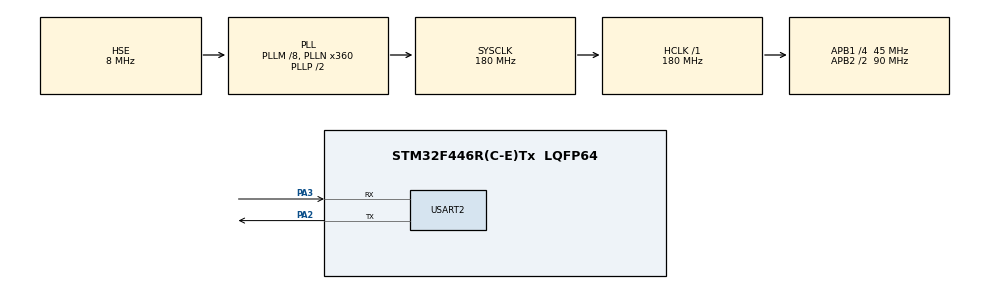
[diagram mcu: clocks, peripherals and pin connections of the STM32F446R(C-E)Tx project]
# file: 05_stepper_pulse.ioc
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Dma.Request0=USART2_RX
Dma.Request1=USART2_TX
Dma.USART2_RX.0.Direction=DMA_PERIPH_TO_MEMORY
Dma.USART2_RX.0.FIFOMode=DMA_FIFOMODE_DISABLE
Dma.USART2_RX.0.Instance=DMA1_Stream5
Dma.USART2_RX.0.MemDataAlignment=DMA_MDATAALIGN_BYTE
Dma.USART2_RX.0.MemInc=DMA_MINC_ENABLE
Dma.USART2_RX.0.Mode=DMA_CIRCULAR
Dma.USART2_RX.0.PeriphDataAlignment=DMA_PDATAALIGN_BYTE
Dma.USART2_RX.0.PeriphInc=DMA_PINC_DISABLE
Dma.USART2_RX.0.Priority=DMA_PRIORITY_LOW
Dma.USART2_TX.1.Direction=DMA_MEMORY_TO_PERIPH
Dma.USART2_TX.1.FIFOMode=DMA_FIFOMODE_DISABLE
Dma.USART2_TX.1.Instance=DMA1_Stream6
Dma.USART2_TX.1.MemDataAlignment=DMA_MDATAALIGN_BYTE
Dma.USART2_TX.1.MemInc=DMA_MINC_ENABLE
Dma.USART2_TX.1.Mode=DMA_NORMAL
Dma.USART2_TX.1.PeriphDataAlignment=DMA_PDATAALIGN_BYTE
Dma.USART2_TX.1.PeriphInc=DMA_PINC_DISABLE
Dma.USART2_TX.1.Priority=DMA_PRIORITY_LOW
Mcu.Family=STM32F4
Mcu.Name=STM32F446R(C-E)Tx
Mcu.Package=LQFP64
NVIC.DMA1_Stream5_IRQn=true\:0\:0\:false\:false\:true\:false\:true\:true
NVIC.DMA1_Stream6_IRQn=true\:0\:0\:false\:false\:true\:false\:true\:true
NVIC.PriorityGroup=NVIC_PRIORITYGROUP_0
NVIC.TIM2_IRQn=true\:0\:0\:false\:false\:true\:true\:true\:true
PA2.Mode=Asynchronous
PA2.Signal=USART2_TX
PA3.Mode=Asynchronous
PA3.Signal=USART2_RX
PH0-OSC_IN.Mode=HSE-External-Clock-Source
PH0-OSC_IN.Signal=RCC_OSC_IN
PH1-OSC_OUT.Mode=HSE-External-Clock-Source
PH1-OSC_OUT.Signal=RCC_OSC_OUT
ProjectManager.HeapSize=0x200
ProjectManager.StackSize=0x400
ProjectManager.TargetToolchain=CMake
RCC.AHBFreq_Value=180000000
RCC.APB1CLKDivider=RCC_HCLK_DIV4
RCC.APB1Freq_Value=45000000
RCC.APB1TimFreq_Value=90000000
RCC.APB2CLKDivider=RCC_HCLK_DIV2
RCC.APB2Freq_Value=90000000
RCC.APB2TimFreq_Value=180000000
RCC.CortexFreq_Value=180000000
RCC.FLatency-AdvancedSettings=FLASH_LATENCY_5
RCC.HCLKFreq_Value=180000000
RCC.HSE_VALUE=8000000
RCC.HSI_VALUE=16000000
RCC.LSE_VALUE=32768
RCC.PLLM=8
RCC.PLLN=360
RCC.PLLSourceVirtual=RCC_PLLSOURCE_HSE
RCC.SYSCLKFreq_VALUE=180000000
RCC.SYSCLKSource=RCC_SYSCLKSOURCE_PLLCLK
RCC.USBFreq_Value=180000000
RCC.VCOOutputFreq_Value=360000000
TIM2.Channel-Output\ Compare1\ No\ Output=TIM_CHANNEL_1
TIM2.Channel-Output\ Compare2\ No\ Output=TIM_CHANNEL_2
TIM2.Channel-Output\ Compare3\ No\ Output=TIM_CHANNEL_3
USART2.VirtualMode=VM_ASYNC
VP_TIM2_VS_ClockSourceINT.Mode=Internal
VP_TIM2_VS_no_output1.Mode=Output Compare1 No Output
VP_TIM2_VS_no_output2.Mode=Output Compare2 No Output
VP_TIM2_VS_no_output3.Mode=Output Compare3 No Output
board=NUCLEO-F446RE

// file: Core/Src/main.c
/* USER CODE BEGIN Header */
/**
  ******************************************************************************
  * @file           : main.c
  * @brief          : Main program body
  ******************************************************************************
  * @attention
  *
  * Copyright (c) 2026 STMicroelectronics.
  * All rights reserved.
  *
  * This software is licensed under terms that can be found in the LICENSE file
  * in the root directory of this software component.
  * If no LICENSE file comes with this software, it is provided AS-IS.
  *
  ******************************************************************************
  */
/* USER CODE END Header */
#include "main.h"

/* USER CODE BEGIN Includes */
#include "stdio.h"
#include "string.h"
/* USER CODE END Includes */

TIM_HandleTypeDef htim2;

UART_HandleTypeDef huart2;
DMA_HandleTypeDef hdma_usart2_rx;
DMA_HandleTypeDef hdma_usart2_tx;

/* USER CODE BEGIN PV */

#define TIM2_CLOCK    90000000UL  // 90 MHz

// Step counters — incremented each OC interrupt
volatile uint32_t stepsZ1 = 0;
volatile uint32_t stepsZ2 = 0;
volatile uint32_t stepsX  = 0;

// Current intervals (ticks between toggles)
uint32_t intervalZ1 = 0;
uint32_t intervalZ2 = 0;
uint32_t intervalX  = 0;

// UART buffer
char uartBuf[64];

/* USER CODE END PV */

void SystemClock_Config(void);
static void MX_GPIO_Init(void);
static void MX_DMA_Init(void);
static void MX_TIM2_Init(void);
static void MX_USART2_UART_Init(void);

/* USER CODE BEGIN 0 */
void setStepVelocity(TIM_HandleTypeDef *htim, uint32_t channel,
                     uint32_t *interval, float stepsPerSec)
{
    if (stepsPerSec < 1.0f)
    {
        // Stop — disable the channel interrupt
        __HAL_TIM_DISABLE_IT(htim, channel == TIM_CHANNEL_1 ? TIM_IT_CC1 :
                                    channel == TIM_CHANNEL_2 ? TIM_IT_CC2 :
                                                               TIM_IT_CC3);
        *interval = 0;
        return;
    }
    *interval = (uint32_t)(TIM2_CLOCK / stepsPerSec);
    // Schedule first compare event
    __HAL_TIM_SET_COMPARE(htim, channel,
        __HAL_TIM_GET_COUNTER(htim) + *interval);
    // Make sure interrupt is enabled
    __HAL_TIM_ENABLE_IT(htim, channel == TIM_CHANNEL_1 ? TIM_IT_CC1 :
                               channel == TIM_CHANNEL_2 ? TIM_IT_CC2 :
                                                          TIM_IT_CC3);
}
/* USER CODE END 0 */

int main(void)
{

  /* MCU Configuration--------------------------------------------------------*/

  /* Reset of all peripherals, Initializes the Flash interface and the Systick. */
  HAL_Init();

  /* Configure the system clock */
  SystemClock_Config();

  /* Initialize all configured peripherals */
  MX_GPIO_Init();
  MX_DMA_Init();
  MX_TIM2_Init();
  MX_USART2_UART_Init();
  /* USER CODE BEGIN 2 */
  HAL_TIM_OC_Start_IT(&htim2, TIM_CHANNEL_1);
  HAL_TIM_OC_Start_IT(&htim2, TIM_CHANNEL_2);
  HAL_TIM_OC_Start_IT(&htim2, TIM_CHANNEL_3);

  // Set all three axes to 500 steps/sec
  setStepVelocity(&htim2, TIM_CHANNEL_1, &intervalZ1, 500.0f);
  setStepVelocity(&htim2, TIM_CHANNEL_2, &intervalZ2, 500.0f);
  setStepVelocity(&htim2, TIM_CHANNEL_3, &intervalX,  500.0f);
  /* USER CODE END 2 */

  /* Infinite loop */
  while (1)
  {
    int len = snprintf(uartBuf, sizeof(uartBuf),
        "Z1:%lu  Z2:%lu  X:%lu\r\n", stepsZ1, stepsZ2, stepsX);
    HAL_UART_Transmit(&huart2, (uint8_t*)uartBuf, len, 100);
    HAL_Delay(500);
  }
}

void SystemClock_Config(void)
{
  RCC_OscInitTypeDef RCC_OscInitStruct = {0};
  RCC_ClkInitTypeDef RCC_ClkInitStruct = {0};

  /** Configure the main internal regulator output voltage
  */
  __HAL_RCC_PWR_CLK_ENABLE();
  __HAL_PWR_VOLTAGESCALING_CONFIG(PWR_REGULATOR_VOLTAGE_SCALE1);

  /** Initializes the RCC Oscillators according to the specified parameters
  * in the RCC_OscInitTypeDef structure.
  */
  RCC_OscInitStruct.OscillatorType = RCC_OSCILLATORTYPE_HSE;
  RCC_OscInitStruct.HSEState = RCC_HSE_BYPASS;
  RCC_OscInitStruct.PLL.PLLState = RCC_PLL_ON;
  RCC_OscInitStruct.PLL.PLLSource = RCC_PLLSOURCE_HSE;
  RCC_OscInitStruct.PLL.PLLM = 8;
  RCC_OscInitStruct.PLL.PLLN = 360;
  RCC_OscInitStruct.PLL.PLLP = RCC_PLLP_DIV2;
  RCC_OscInitStruct.PLL.PLLQ = 2;
  RCC_OscInitStruct.PLL.PLLR = 2;
  if (HAL_RCC_OscConfig(&RCC_OscInitStruct) != HAL_OK)
  {
    Error_Handler();
  }

  /** Activate the Over-Drive mode
  */
  if (HAL_PWREx_EnableOverDrive() != HAL_OK)
  {
    Error_Handler();
  }

  /** Initializes the CPU, AHB and APB buses clocks
  */
  RCC_ClkInitStruct.ClockType = RCC_CLOCKTYPE_HCLK|RCC_CLOCKTYPE_SYSCLK
                              |RCC_CLOCKTYPE_PCLK1|RCC_CLOCKTYPE_PCLK2;
  RCC_ClkInitStruct.SYSCLKSource = RCC_SYSCLKSOURCE_PLLCLK;
  RCC_ClkInitStruct.AHBCLKDivider = RCC_SYSCLK_DIV1;
  RCC_ClkInitStruct.APB1CLKDivider = RCC_HCLK_DIV4;
  RCC_ClkInitStruct.APB2CLKDivider = RCC_HCLK_DIV2;

  if (HAL_RCC_ClockConfig(&RCC_ClkInitStruct, FLASH_LATENCY_5) != HAL_OK)
  {
    Error_Handler();
  }
}

static void MX_TIM2_Init(void)
{

  TIM_ClockConfigTypeDef sClockSourceConfig = {0};
  TIM_MasterConfigTypeDef sMasterConfig = {0};
  TIM_OC_InitTypeDef sConfigOC = {0};

  htim2.Instance = TIM2;
  htim2.Init.Prescaler = 0;
  htim2.Init.CounterMode = TIM_COUNTERMODE_UP;
  htim2.Init.Period = 4294967295;
  htim2.Init.ClockDivision = TIM_CLOCKDIVISION_DIV1;
  htim2.Init.AutoReloadPreload = TIM_AUTORELOAD_PRELOAD_DISABLE;
  if (HAL_TIM_Base_Init(&htim2) != HAL_OK)
  {
    Error_Handler();
  }
  sClockSourceConfig.ClockSource = TIM_CLOCKSOURCE_INTERNAL;
  if (HAL_TIM_ConfigClockSource(&htim2, &sClockSourceConfig) != HAL_OK)
  {
    Error_Handler();
  }
  if (HAL_TIM_OC_Init(&htim2) != HAL_OK)
  {
    Error_Handler();
  }
  sMasterConfig.MasterOutputTrigger = TIM_TRGO_RESET;
  sMasterConfig.MasterSlaveMode = TIM_MASTERSLAVEMODE_DISABLE;
  if (HAL_TIMEx_MasterConfigSynchronization(&htim2, &sMasterConfig) != HAL_OK)
  {
    Error_Handler();
  }
  sConfigOC.OCMode = TIM_OCMODE_TIMING;
  sConfigOC.Pulse = 0;
  sConfigOC.OCPolarity = TIM_OCPOLARITY_HIGH;
  sConfigOC.OCFastMode = TIM_OCFAST_DISABLE;
  if (HAL_TIM_OC_ConfigChannel(&htim2, &sConfigOC, TIM_CHANNEL_1) != HAL_OK)
  {
    Error_Handler();
  }
  if (HAL_TIM_OC_ConfigChannel(&htim2, &sConfigOC, TIM_CHANNEL_2) != HAL_OK)
  {
    Error_Handler();
  }
  if (HAL_TIM_OC_ConfigChannel(&htim2, &sConfigOC, TIM_CHANNEL_3) != HAL_OK)
  {
    Error_Handler();
  }

}

static void MX_USART2_UART_Init(void)
{

  huart2.Instance = USART2;
  huart2.Init.BaudRate = 115200;
  huart2.Init.WordLength = UART_WORDLENGTH_8B;
  huart2.Init.StopBits = UART_STOPBITS_1;
  huart2.Init.Parity = UART_PARITY_NONE;
  huart2.Init.Mode = UART_MODE_TX_RX;
  huart2.Init.HwFlowCtl = UART_HWCONTROL_NONE;
  huart2.Init.OverSampling = UART_OVERSAMPLING_16;
  if (HAL_UART_Init(&huart2) != HAL_OK)
  {
    Error_Handler();
  }

}

static void MX_DMA_Init(void)
{

  /* DMA controller clock enable */
  __HAL_RCC_DMA1_CLK_ENABLE();

  /* DMA interrupt init */
  /* DMA1_Stream5_IRQn interrupt configuration */
  HAL_NVIC_SetPriority(DMA1_Stream5_IRQn, 0, 0);
  HAL_NVIC_EnableIRQ(DMA1_Stream5_IRQn);
  /* DMA1_Stream6_IRQn interrupt configuration */
  HAL_NVIC_SetPriority(DMA1_Stream6_IRQn, 0, 0);
  HAL_NVIC_EnableIRQ(DMA1_Stream6_IRQn);

}

static void MX_GPIO_Init(void)
{

  /* GPIO Ports Clock Enable */
  __HAL_RCC_GPIOH_CLK_ENABLE();
  __HAL_RCC_GPIOA_CLK_ENABLE();

}

/* USER CODE BEGIN 4 */
void HAL_TIM_OC_DelayElapsedCallback(TIM_HandleTypeDef *htim)
{
    if (htim->Instance == TIM2)
    {
        if (htim->Channel == HAL_TIM_ACTIVE_CHANNEL_1)
        {
            __HAL_TIM_SET_COMPARE(&htim2, TIM_CHANNEL_1,
                __HAL_TIM_GET_COMPARE(&htim2, TIM_CHANNEL_1) + intervalZ1);
            stepsZ1++;
        }
        if (htim->Channel == HAL_TIM_ACTIVE_CHANNEL_2)
        {
            __HAL_TIM_SET_COMPARE(&htim2, TIM_CHANNEL_2,
                __HAL_TIM_GET_COMPARE(&htim2, TIM_CHANNEL_2) + intervalZ2);
            stepsZ2++;
        }
        if (htim->Channel == HAL_TIM_ACTIVE_CHANNEL_3)
        {
            __HAL_TIM_SET_COMPARE(&htim2, TIM_CHANNEL_3,
                __HAL_TIM_GET_COMPARE(&htim2, TIM_CHANNEL_3) + intervalX);
            stepsX++;
        }
    }
}
/* USER CODE END 4 */

void Error_Handler(void)
{
  __disable_irq();
  while (1)
  {
  }
}
